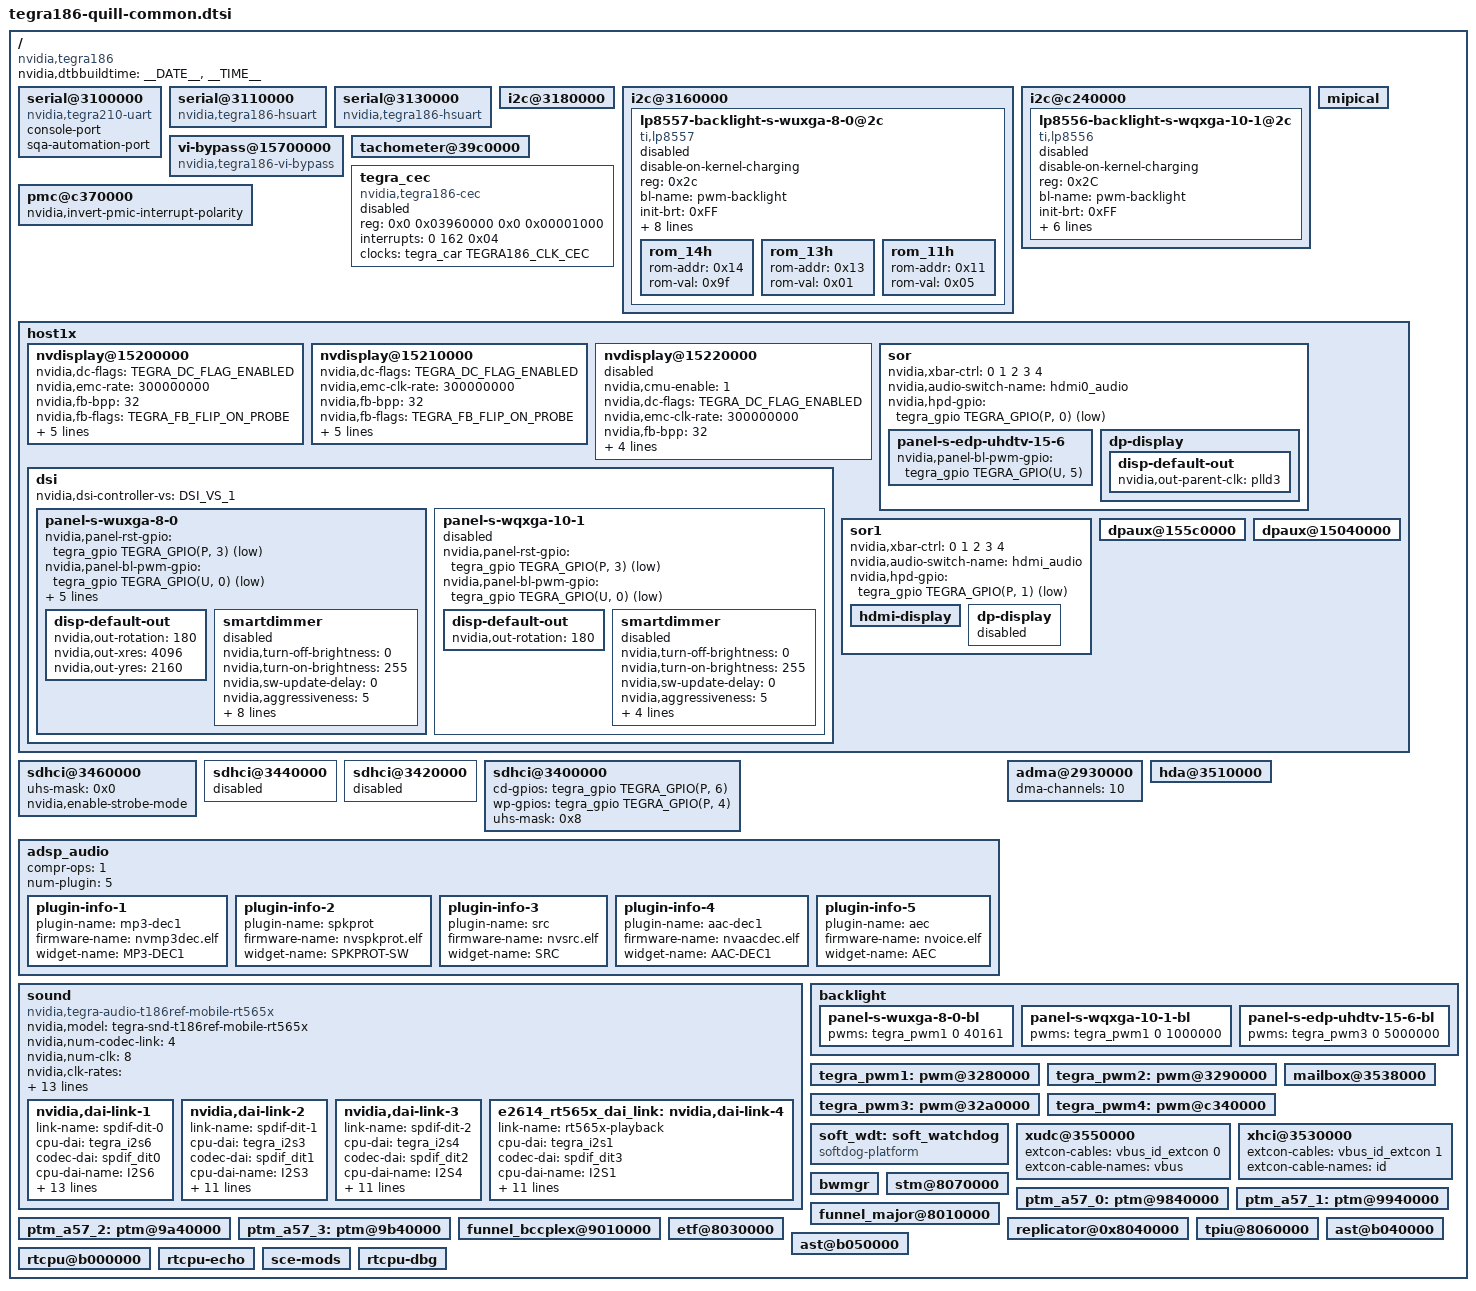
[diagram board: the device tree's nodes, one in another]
/*
 * tegra186-quill-common.dtsi: Quill common dtsi.
 *
 * Copyright (c) 2015-2016, NVIDIA CORPORATION.  All rights reserved.
 *
 * This program is free software; you can redistribute it and/or modify
 * it under the terms of the GNU General Public License as published by
 * the Free Software Foundation; version 2 of the License.
 *
 * This program is distributed in the hope that it will be useful, but WITHOUT
 * ANY WARRANTY; without even the implied warranty of MERCHANTABILITY or
 * FITNESS FOR A PARTICULAR PURPOSE.  See the GNU General Public License for
 * more details.
 */

#include <dt-bindings/types.h>
#include <dt-bindings/gpio/tegra-gpio.h>
/dts-v1/;

/memreserve/ 0x80000000 0x00010000;

#include "tegra186-soc/tegra186-soc-cvm.dtsi"
#include "tegra186-platforms-simple-bus.dtsi"
#include "panel-s-wuxga-8-0.dtsi"
#include "panel-s-wqxga-10-1.dtsi"
#include "tegra186-platforms/tegra186-quill-eqos.dtsi"
#include "tegra186-hdmi.dtsi"
#include "tegra186-dp.dtsi"
#include "panel-s-edp-uhdtv-15-6.dtsi"
#include "tegra186-quill-pwm-fan.dtsi"
#include "tegra186-quill-thermal-fan-est.dtsi"

/ {
        compatible = "nvidia,tegra186";

        nvidia,dtbbuildtime = __DATE__, __TIME__;
        #address-cells = <2>;
        #size-cells = <2>;

	serial@3100000 {
		compatible = "nvidia,tegra210-uart", "nvidia,tegra186-hsuart";
		console-port;
		sqa-automation-port;
		status = "okay";
	};

	serial@3110000 {
		compatible = "nvidia,tegra186-hsuart";
		status = "okay";
	};

	serial@3130000 {
		compatible = "nvidia,tegra186-hsuart";
		dma-names = "tx";
		status = "okay";
	};

	i2c@3180000 {
		status = "okay";
	};

	i2c@3160000 {
		status = "okay";
		lp8557-backlight-s-wuxga-8-0@2c {
			status = "disabled";
			disable-on-kernel-charging;
			compatible = "ti,lp8557";
			reg = <0x2c>;

			bl-name = "pwm-backlight"; /* Match liblights naming expectations */
			init-brt = /bits/ 8 <0xFF>; /* Max brightness */
			dev-ctrl = /bits/ 8 <0x80>; /* PWM, enable standby mode */
			pwm-period = <40161>;

			pwm-names = "lp8557";
			pwms = <&tegra_pwm1 0 40161>;

			bl-measured = < 0 1 2 3 4 5 5 6
					7 8 9 10 11 11 12 13
					14 15 15 16 17 18 19 20
					21 22 22 23 24 25 26 27
					28 29 30 31 31 32 33 34
					35 36 37 37 38 39 40 41
					41 42 43 44 45 46 47 48
					48 49 50 51 52 53 54 54
					55 56 57 58 58 59 60 61
					62 63 64 65 66 67 68 69
					70 71 72 73 74 75 75 76
					77 78 79 80 81 82 83 84
					85 86 87 88 89 90 91 92
					93 94 94 95 96 97 98 99
					100 101 102 104 105 106 107 108
					109 110 111 112 113 114 115 116
					117 118 119 120 121 122 123 125
					126 127 128 129 130 131 132 133
					134 135 136 137 138 139 140 141
					142 143 144 146 147 148 149 150
					151 152 153 154 155 156 157 158
					159 160 161 162 163 164 165 167
					168 169 170 171 172 173 174 175
					176 178 179 180 181 182 183 184
					185 186 187 188 189 190 191 192
					193 194 195 196 197 199 200 201
					202 203 204 205 206 207 208 210
					211 212 213 214 215 216 217 219
					220 221 222 223 225 226 227 228
					229 230 231 233 234 235 236 237
					238 239 240 241 242 244 245 246
					247 248 249 250 251 253 254 255 >;

			bl-curve = < 0 1 1 2 2 3 3 4
					4 5 5 6 7 7 8 8
					9 9 10 10 11 11 12 12
					13 14 14 15 15 16 16 17
					17 18 18 19 20 20 21 21
					22 22 23 23 24 24 25 25
					26 27 27 28 28 29 29 30
					30 31 31 32 33 33 34 34
					35 35 36 36 37 37 38 38
					39 40 40 41 41 42 42 43
					43 44 44 45 46 46 47 47
					48 48 49 49 50 50 51 52
					52 53 53 54 54 55 55 56
					56 57 57 58 59 59 60 60
					61 61 62 62 63 63 64 65
					65 66 66 67 67 68 68 69
					69 70 70 71 72 72 73 73
					74 74 75 75 76 76 77 78
					78 79 79 80 80 81 81 82
					82 83 83 84 85 85 86 86
					87 87 88 88 89 89 90 92
					94 96 97 99 101 103 105 107
					109 110 112 114 116 118 120 122
					123 125 127 129 131 133 134 136
					138 140 142 144 146 147 149 151
					153 155 157 159 160 162 164 166
					168 170 172 173 175 177 179 181
					183 185 186 188 190 192 194 196
					198 199 201 203 205 207 209 211
					212 214 216 218 220 222 223 225
					227 229 231 233 235 236 238 240
					242 244 246 248 249 251 253 255 >;

			/* 5 LED string */
			rom_14h {
				rom-addr = /bits/ 8 <0x14>;
				rom-val = /bits/ 8 <0x9f>;
			};

			/*Boost freq 1MHZ*/
			rom_13h {
				rom-addr = /bits/ 8 <0x13>;
				rom-val = /bits/ 8 <0x01>;
			};

			/*20mA max */
			rom_11h {
				rom-addr = /bits/ 8 <0x11>;
				rom-val = /bits/ 8 <0x05>;
			};
		};
	};

	i2c@c240000 {
		status = "okay";
		lp8556-backlight-s-wqxga-10-1@2c {
			status = "disabled";
			disable-on-kernel-charging;
			compatible = "ti,lp8556";
			reg = <0x2C>;

			bl-name = "pwm-backlight"; /* Match liblights naming expectations */
			init-brt = /bits/ 8 <0xFF>; /* Max brightness */
			dev-ctrl = /bits/ 8 <0x80>; /* PWM, enable standby mode */
			pwm-period = <40161>;

			pwm-names = "lp8556";
			pwms = <&tegra_pwm1 0 40161>;

			bl-measured = < 0 1 2 3 4 5 5 6
					7 8 9 10 11 11 12 13
					14 15 15 16 17 18 19 20
					21 22 22 23 24 25 26 27
					28 29 30 31 31 32 33 34
					35 36 37 37 38 39 40 41
					41 42 43 44 45 46 47 48
					48 49 50 51 52 53 54 54
					55 56 57 58 58 59 60 61
					62 63 64 65 66 67 68 69
					70 71 72 73 74 75 75 76
					77 78 79 80 81 82 83 84
					85 86 87 88 89 90 91 92
					93 94 94 95 96 97 98 99
					100 101 102 104 105 106 107 108
					109 110 111 112 113 114 115 116
					117 118 119 120 121 122 123 125
					126 127 128 129 130 131 132 133
					134 135 136 137 138 139 140 141
					142 143 144 146 147 148 149 150
					151 152 153 154 155 156 157 158
					159 160 161 162 163 164 165 167
					168 169 170 171 172 173 174 175
					176 178 179 180 181 182 183 184
					185 186 187 188 189 190 191 192
					193 194 195 196 197 199 200 201
					202 203 204 205 206 207 208 210
					211 212 213 214 215 216 217 219
					220 221 222 223 225 226 227 228
					229 230 231 233 234 235 236 237
					238 239 240 241 242 244 245 246
					247 248 249 250 251 253 254 255 >;
		};

	};

	vi-bypass@15700000{
		compatible = "nvidia,tegra186-vi-bypass";
		status = "okay";
	};

	tachometer@39c0000 {
		status = "okay";
	};

	tegra_cec {
		status = "disabled";
		compatible = "nvidia,tegra186-cec";
		reg = <0x0 0x03960000 0x0 0x00001000>;
		interrupts = <0 162 0x04>;
		clocks = <&tegra_car TEGRA186_CLK_CEC>;
		clock-names = "cec";
	};

	pmc@c370000 {
		nvidia,invert-pmic-interrupt-polarity;
	};

        mipical {
                status = "okay";
        };

	host1x {
		nvdisplay@15200000 {
                        status = "okay";
                        nvidia,dc-flags = <TEGRA_DC_FLAG_ENABLED>;
                        nvidia,emc-rate = <300000000>;
                        nvidia,fb-bpp = <32>;
                        nvidia,fb-flags = <TEGRA_FB_FLIP_ON_PROBE>;
			nvidia,fb-win = <0>;
			win-mask = <0x7>;
			nvidia,dc-ctrlnum = <0>;
			nvidia,dc-or-node = "/host1x/dsi";
			nvidia,cmu-enable = <1>;
                };

		nvdisplay@15210000 {
			status = "okay";
			nvidia,dc-flags = <TEGRA_DC_FLAG_ENABLED>;
			nvidia,emc-clk-rate = <300000000>;
			nvidia,fb-bpp = <32>; /* bits per pixel */
			nvidia,fb-flags = <TEGRA_FB_FLIP_ON_PROBE>;
			nvidia,fb-win = <3>;
			win-mask = <0x38>;
			nvidia,dc-ctrlnum = <1>;
			nvidia,dc-or-node = "/host1x/sor1";
			nvidia,cmu-enable = <1>;
		};

		nvdisplay@15220000 {
			nvidia,cmu-enable = <1>;
		};

		nvdisplay@15220000 {
			status = "disabled";
			nvidia,dc-flags = <TEGRA_DC_FLAG_ENABLED>;
			nvidia,emc-clk-rate = <300000000>;
			nvidia,fb-bpp = <32>; /* bits per pixel */
			nvidia,fb-flags = <TEGRA_FB_FLIP_ON_PROBE>;
			win-mask = <0x0>;
			nvidia,dc-ctrlnum = <2>;
			nvidia,dc-or-node = "/host1x/sor";
		};

		dsi {	/* dsi@15300000 */
			nvidia,dsi-controller-vs = <DSI_VS_1>;
			status = "okay";
			panel-s-wuxga-8-0 {
				status = "okay";
				nvidia,panel-rst-gpio = <&tegra_gpio TEGRA_GPIO(P, 3) 1>; /* PP3 */
				nvidia,panel-bl-pwm-gpio = <&tegra_gpio TEGRA_GPIO(U, 0) 1>; /* PU0 */
				nvidia,panel-bl-en-gpio = <&tegra_gpio TEGRA_GPIO(U, 3) 1>; /* PU3 */
				nvidia,panel-en-gpio = <&gpio_i2c_0_77 4 1>; /* tca9539 0x77 Pin 4 */
				nvidia,en-vmm-vpp-with-i2c-config;
				nvidia,default_color_space = <0>;
				disp-default-out {
					nvidia,out-rotation = <180>;
					nvidia,out-xres = <4096>;
					nvidia,out-yres = <2160>;
                                };
				smartdimmer {
					status = "disabled";
					nvidia,turn-off-brightness = <0>;
					nvidia,turn-on-brightness = <255>;
					nvidia,sw-update-delay = <0>;
					nvidia,aggressiveness = <5>;
					nvidia,phase-in-settings = <0>;
					nvidia,phase-in-adjustments = <0>;
					nvidia,sd-window-enable = <0>;
					nvidia,bl-device-name = "pwm-backlight";
					nvidia,gain_table = <
						0x4000 0x4000 0x4000 0x4000 0x4000 0x4000 0x4000 0x4000
						0x4000 0x4000 0x4000 0x4000 0x4000 0x4000 0x4000 0x4000
						0x4000 0x4000 0x4000 0x4000 0x4000 0x4000 0x4000 0x4000
						0x4000 0x4000 0x4000 0x4000 0x4000 0x4000 0x4000 0x4000
						0x4144 0x4144 0x4144 0x4144 0x4144 0x4144 0x4144 0x4144
						0x4144 0x4144 0x4144 0x4144 0x4144 0x4144 0x4144 0x4144
						0x4144 0x4144 0x4144 0x4144 0x4144 0x4144 0x4144 0x4144
						0x4144 0x4144 0x4144 0x4144 0x4144 0x4144 0x4144 0x4128
						0x428c 0x428c 0x428c 0x428c 0x428c 0x428c 0x428c 0x428c
						0x428c 0x428c 0x428c 0x428c 0x428c 0x428c 0x428c 0x428c
						0x428c 0x428c 0x428c 0x428c 0x428c 0x428c 0x428c 0x428c
						0x428c 0x428c 0x428c 0x428c 0x428c 0x428c 0x4260 0x4170
						0x43d4 0x43d4 0x43d4 0x43d4 0x43d4 0x43d4 0x43d4 0x43d4
						0x43d4 0x43d4 0x43d4 0x43d4 0x43d4 0x43d4 0x43d4 0x43d4
						0x43d4 0x43d4 0x43d4 0x43d4 0x43d4 0x43d4 0x43d4 0x43d4
						0x43d4 0x43d4 0x43d4 0x43d4 0x43d4 0x439c 0x42d0 0x4184
						0x451c 0x451c 0x451c 0x451c 0x451c 0x451c 0x451c 0x451c
						0x451c 0x451c 0x451c 0x451c 0x451c 0x451c 0x451c 0x451c
						0x451c 0x451c 0x451c 0x451c 0x451c 0x451c 0x451c 0x451c
						0x451c 0x451c 0x451c 0x451c 0x44ec 0x443c 0x4320 0x419c
						0x4664 0x4664 0x4664 0x4664 0x4664 0x4664 0x4664 0x4664
						0x4664 0x4664 0x4664 0x4664 0x4664 0x4664 0x4664 0x4664
						0x4664 0x4664 0x4664 0x4664 0x4664 0x4664 0x4664 0x4664
						0x4664 0x4664 0x4664 0x4620 0x457c 0x447c 0x432c 0x4198
						0x47ac 0x47ac 0x47ac 0x47ac 0x47ac 0x47ac 0x47ac 0x47ac
						0x47ac 0x47ac 0x47ac 0x47ac 0x47ac 0x47ac 0x47ac 0x47ac
						0x47ac 0x47ac 0x47ac 0x47ac 0x47ac 0x47ac 0x47ac 0x47ac
						0x47ac 0x47ac 0x476c 0x46d8 0x45f0 0x44bc 0x434c 0x41a0
						0x48f4 0x48f4 0x48f4 0x48f4 0x48f4 0x48f4 0x48f4 0x48f4
						0x48f4 0x48f4 0x48f4 0x48f4 0x48f4 0x48f4 0x48f4 0x48f4
						0x48f4 0x48f4 0x48f4 0x48f4 0x48f4 0x48f4 0x48f4 0x48f4
						0x48f4 0x48b8 0x482c 0x4758 0x463c 0x44e8 0x4360 0x41a4
						0x4a3c 0x4a3c 0x4a3c 0x4a3c 0x4a3c 0x4a3c 0x4a3c 0x4a3c
						0x4a3c 0x4a3c 0x4a3c 0x4a3c 0x4a3c 0x4a3c 0x4a3c 0x4a3c
						0x4a3c 0x4a3c 0x4a3c 0x4a3c 0x4a3c 0x4a3c 0x4a3c 0x4a3c
						0x4a04 0x4980 0x48b8 0x47b0 0x4674 0x4504 0x4368 0x41a8
						0x4b84 0x4b84 0x4b84 0x4b84 0x4b84 0x4b84 0x4b84 0x4b84
						0x4b84 0x4b84 0x4b84 0x4b84 0x4b84 0x4b84 0x4b84 0x4b84
						0x4b84 0x4b84 0x4b84 0x4b84 0x4b84 0x4b84 0x4b84 0x4b64
						0x4af4 0x4a3c 0x4948 0x481c 0x46c0 0x4538 0x4388 0x41b4
						0x4ccc 0x4ccc 0x4ccc 0x4ccc 0x4ccc 0x4ccc 0x4ccc 0x4ccc
						0x4ccc 0x4ccc 0x4ccc 0x4ccc 0x4ccc 0x4ccc 0x4ccc 0x4ccc
						0x4ccc 0x4ccc 0x4ccc 0x4ccc 0x4ccc 0x4ccc 0x4cac 0x4c40
						0x4b94 0x4aac 0x4990 0x4848 0x46d4 0x4540 0x4384 0x41b0
						0x4e14 0x4e14 0x4e14 0x4e14 0x4e14 0x4e14 0x4e14 0x4e14
						0x4e14 0x4e14 0x4e14 0x4e14 0x4e14 0x4e14 0x4e14 0x4e14
						0x4e14 0x4e14 0x4e14 0x4e14 0x4e14 0x4e04 0x4dac 0x4d10
						0x4c38 0x4b2c 0x49f0 0x4890 0x4708 0x455c 0x4398 0x41b8
						0x4f5c 0x4f5c 0x4f5c 0x4f5c 0x4f5c 0x4f5c 0x4f5c 0x4f5c
						0x4f5c 0x4f5c 0x4f5c 0x4f5c 0x4f5c 0x4f5c 0x4f5c 0x4f5c
						0x4f5c 0x4f5c 0x4f5c 0x4f5c 0x4f4c 0x4ef4 0x4e60 0x4d90
						0x4c90 0x4b64 0x4a10 0x489c 0x4708 0x4558 0x4390 0x41b0
						0x50a0 0x50a0 0x50a0 0x50a0 0x50a0 0x50a0 0x50a0 0x50a0
						0x50a0 0x50a0 0x50a0 0x50a0 0x50a0 0x50a0 0x50a0 0x50a0
						0x50a0 0x50a0 0x50a0 0x509c 0x5058 0x4fd4 0x4f10 0x4e20
						0x4d00 0x4bb8 0x4a50 0x48c8 0x4728 0x456c 0x439c 0x41b4
						0x51e8 0x51e8 0x51e8 0x51e8 0x51e8 0x51e8 0x51e8 0x51e8
						0x51e8 0x51e8 0x51e8 0x51e8 0x51e8 0x51e8 0x51e8 0x51e8
						0x51e8 0x51e8 0x51e8 0x51b8 0x5140 0x5090 0x4fa8 0x4e94
						0x4d5c 0x4c00 0x4a84 0x48ec 0x4740 0x4578 0x43a0 0x41b8
						0x5330 0x5330 0x5330 0x5330 0x5330 0x5330 0x5330 0x5330
						0x5330 0x5330 0x5330 0x5330 0x5330 0x5330 0x5330 0x5330
						0x5330 0x5330 0x5314 0x52ac 0x5208 0x5130 0x5028 0x4ef8
						0x4da8 0x4c38 0x4aac 0x4908 0x4750 0x4584 0x43a8 0x41b8
						0x5478 0x5478 0x5478 0x5478 0x5478 0x5478 0x5478 0x5478
						0x5478 0x5478 0x5478 0x5478 0x5478 0x5478 0x5478 0x5478
						0x5478 0x5468 0x5414 0x537c 0x52b0 0x51b4 0x5090 0x4f48
						0x4de4 0x4c64 0x4acc 0x491c 0x475c 0x4588 0x43a8 0x41b8
						0x55c0 0x55c0 0x55c0 0x55c0 0x55c0 0x55c0 0x55c0 0x55c0
						0x55c0 0x55c0 0x55c0 0x55c0 0x55c0 0x55c0 0x55c0 0x55c0
						0x55bc 0x5574 0x54ec 0x542c 0x533c 0x5224 0x50e8 0x4f8c
						0x4e14 0x4c84 0x4ae0 0x492c 0x4764 0x458c 0x43a8 0x41b8
						0x5708 0x5708 0x5708 0x5708 0x5708 0x5708 0x5708 0x5708
						0x5708 0x5708 0x5708 0x5708 0x5708 0x5708 0x5708 0x5708
						0x56d4 0x565c 0x55a8 0x54c0 0x53b0 0x5280 0x512c 0x4fbc
						0x4e38 0x4c9c 0x4af0 0x4934 0x4764 0x458c 0x43a8 0x41b8
						0x5850 0x5850 0x5850 0x5850 0x5850 0x5850 0x5850 0x5850
						0x5850 0x5850 0x5850 0x5850 0x5850 0x5850 0x5850 0x5830
						0x57c4 0x571c 0x5644 0x553c 0x5410 0x52c8 0x5160 0x4fe4
						0x4e50 0x4cac 0x4af8 0x4934 0x4764 0x458c 0x43a4 0x41b4
						0x5998 0x5998 0x5998 0x5998 0x5998 0x5998 0x5998 0x5998
						0x5998 0x5998 0x5998 0x5998 0x5998 0x5998 0x5990 0x5948
						0x58bc 0x57f4 0x56fc 0x55dc 0x549c 0x5340 0x51c8 0x503c
						0x4e9c 0x4ce8 0x4b28 0x495c 0x4784 0x45a0 0x43b0 0x41bc
						0x5ae0 0x5ae0 0x5ae0 0x5ae0 0x5ae0 0x5ae0 0x5ae0 0x5ae0
						0x5ae0 0x5ae0 0x5ae0 0x5ae0 0x5ae0 0x5ae0 0x5aa8 0x5a28
						0x596c 0x5880 0x5768 0x5630 0x54d8 0x5368 0x51e4 0x504c
						0x4ea0 0x4cec 0x4b24 0x4954 0x477c 0x4598 0x43ac 0x41b8
						0x5c28 0x5c28 0x5c28 0x5c28 0x5c28 0x5c28 0x5c28 0x5c28
						0x5c28 0x5c28 0x5c28 0x5c28 0x5c28 0x5c14 0x5bb4 0x5b10
						0x5a38 0x5930 0x5800 0x56b4 0x554c 0x53cc 0x5238 0x5090
						0x4edc 0x4d1c 0x4b4c 0x4974 0x4790 0x45a8 0x43b4 0x41bc
						0x5d70 0x5d70 0x5d70 0x5d70 0x5d70 0x5d70 0x5d70 0x5d70
						0x5d70 0x5d70 0x5d70 0x5d70 0x5d68 0x5d18 0x5c84 0x5bb0
						0x5ab0 0x598c 0x5844 0x56e0 0x5568 0x53dc 0x523c 0x5090
						0x4ed4 0x4d10 0x4b40 0x4964 0x4784 0x459c 0x43ac 0x41b8
						0x5eb8 0x5eb8 0x5eb8 0x5eb8 0x5eb8 0x5eb8 0x5eb8 0x5eb8
						0x5eb8 0x5eb8 0x5eb8 0x5eb8 0x5e90 0x5e18 0x5d60 0x5c70
						0x5b54 0x5a18 0x58bc 0x574c 0x55c0 0x5428 0x527c 0x50c4
						0x4f00 0x4d34 0x4b5c 0x497c 0x4794 0x45a8 0x43b4 0x41bc
						0x6000 0x6000 0x6000 0x6000 0x6000 0x6000 0x6000 0x6000
						0x6000 0x6000 0x6000 0x5ff8 0x5fa4 0x5f04 0x5e28 0x5d1c
						0x5be8 0x5a98 0x592c 0x57a8 0x5610 0x5468 0x52b4 0x50f4
						0x4f28 0x4d54 0x4b74 0x4990 0x47a4 0x45b0 0x43bc 0x41c0
						0x6144 0x6144 0x6144 0x6144 0x6144 0x6144 0x6144 0x6144
						0x6144 0x6144 0x6144 0x6104 0x6074 0x5fa0 0x5e9c 0x5d70
						0x5c24 0x5abc 0x593c 0x57ac 0x5608 0x545c 0x52a0 0x50dc
						0x4f0c 0x4d38 0x4b5c 0x4978 0x4790 0x45a0 0x43b0 0x41b8
						0x628c 0x628c 0x628c 0x628c 0x628c 0x628c 0x628c 0x628c
						0x628c 0x628c 0x6278 0x6208 0x614c 0x605c 0x5f3c 0x5df8
						0x5c94 0x5b1c 0x5990 0x57f0 0x5644 0x548c 0x52c8 0x50fc
						0x4f28 0x4d4c 0x4b6c 0x4984 0x4798 0x45a8 0x43b4 0x41bc
						0x63d4 0x63d4 0x63d4 0x63d4 0x63d4 0x63d4 0x63d4 0x63d4
						0x63d4 0x63d4 0x6390 0x62f4 0x6214 0x6100 0x5fc8 0x5e70
						0x5cfc 0x5b74 0x59d8 0x5830 0x5678 0x54b8 0x52ec 0x5118
						0x4f40 0x4d60 0x4b78 0x4990 0x47a0 0x45ac 0x43b4 0x41bc
						0x651c 0x651c 0x651c 0x651c 0x651c 0x651c 0x651c 0x651c
						0x651c 0x6504 0x648c 0x63c4 0x62c4 0x6198 0x6044 0x5ed8
						0x5d54 0x5bbc 0x5a14 0x5860 0x56a4 0x54d8 0x5308 0x5130
						0x4f50 0x4d6c 0x4b84 0x4994 0x47a4 0x45b0 0x43b8 0x41bc
						0x6664 0x6664 0x6664 0x6664 0x6664 0x6664 0x6664 0x6664
						0x6664 0x6618 0x6570 0x6480 0x6360 0x6218 0x60b4 0x5f34
						0x5da0 0x5bfc 0x5a4c 0x588c 0x56c4 0x54f4 0x5320 0x5140
						0x4f60 0x4d78 0x4b8c 0x499c 0x47a8 0x45b0 0x43b8 0x41bc
						0x67ac 0x67ac 0x67ac 0x67ac 0x67ac 0x67ac 0x67ac 0x67ac
						0x6790 0x670c 0x6638 0x6528 0x63ec 0x628c 0x6110 0x5f80
						0x5de0 0x5c30 0x5a74 0x58b0 0x56e0 0x550c 0x5330 0x5150
						0x4f68 0x4d7c 0x4b90 0x499c 0x47a8 0x45b0 0x43b8 0x41bc
						0x68f4 0x68f4 0x68f4 0x68f4 0x68f4 0x68f4 0x68f4 0x68f4
						0x68a0 0x67e8 0x66e8 0x65b8 0x6460 0x62ec 0x6160 0x5fc4
						0x5e14 0x5c5c 0x5a98 0x58c8 0x56f4 0x551c 0x533c 0x5158
						0x4f6c 0x4d80 0x4b90 0x499c 0x47a8 0x45b0 0x43b8 0x41bc
						0x6a3c 0x6a3c 0x6a3c 0x6a3c 0x6a3c 0x6a3c 0x6a3c 0x6a1c
						0x698c 0x68a4 0x6784 0x6634 0x64c4 0x633c 0x61a4 0x5ff8
						0x5e40 0x5c7c 0x5ab0 0x58dc 0x5704 0x5524 0x5340 0x5158
						0x4f70 0x4d80 0x4b90 0x499c 0x47a8 0x45b0 0x43b4 0x41bc
						0x6b84 0x6b84 0x6b84 0x6b84 0x6b84 0x6b84 0x6b80 0x6b24
						0x6a5c 0x6948 0x6804 0x669c 0x6518 0x6380 0x61d4 0x6020
						0x5e5c 0x5c94 0x5ac0 0x58e8 0x570c 0x5528 0x5344 0x5158
						0x4f6c 0x4d7c 0x4b8c 0x4998 0x47a4 0x45ac 0x43b4 0x41b8
						0x6ccc 0x6ccc 0x6ccc 0x6ccc 0x6ccc 0x6ccc 0x6cc0 0x6c3c
						0x6b54 0x6a2c 0x68d4 0x6758 0x65c8 0x6420 0x6268 0x60a8
						0x5ed8 0x5d04 0x5b28 0x5948 0x5760 0x5578 0x5388 0x5198
						0x4fa4 0x4dac 0x4bb4 0x49b8 0x47bc 0x45c0 0x43c0 0x41c0
						0x6e14 0x6e14 0x6e14 0x6e14 0x6e14 0x6e14 0x6dd0 0x6d0c
						0x6bf4 0x6aa4 0x6930 0x67a0 0x65fc 0x6448 0x6288 0x60bc
						0x5ee8 0x5d0c 0x5b2c 0x5948 0x575c 0x5570 0x5380 0x5190
						0x4f9c 0x4da4 0x4bac 0x49b0 0x47b8 0x45b8 0x43bc 0x41bc
						0x6f5c 0x6f5c 0x6f5c 0x6f5c 0x6f5c 0x6f4c 0x6eb8 0x6db8
						0x6c74 0x6b08 0x697c 0x67d8 0x6624 0x6464 0x6298 0x60c4
						0x5ee8 0x5d08 0x5b24 0x593c 0x5754 0x5564 0x5374 0x5184
						0x4f8c 0x4d98 0x4ba0 0x49a8 0x47b0 0x45b4 0x43b8 0x41bc
						0x70a0 0x70a0 0x70a0 0x70a0 0x70a0 0x7054 0x6f74 0x6e40
						0x6cdc 0x6b50 0x69b0 0x67fc 0x663c 0x6470 0x629c 0x60c4
						0x5ee4 0x5d00 0x5b18 0x5930 0x5744 0x5554 0x5364 0x5174
						0x4f80 0x4d88 0x4b94 0x499c 0x47a4 0x45ac 0x43b4 0x41b8
						0x71e8 0x71e8 0x71e8 0x71e8 0x71e8 0x7168 0x7064 0x6f14
						0x6d98 0x6bfc 0x6a4c 0x688c 0x66c0 0x64e8 0x630c 0x612c
						0x5f44 0x5d58 0x5b6c 0x5978 0x5788 0x5590 0x539c 0x51a4
						0x4fa8 0x4db0 0x4bb4 0x49b8 0x47b8 0x45bc 0x43bc 0x41bc
						0x7330 0x7330 0x7330 0x7330 0x7300 0x7220 0x70e4 0x6f6c
						0x6dd0 0x6c20 0x6a60 0x6894 0x66bc 0x64e0 0x62fc 0x6118
						0x5f2c 0x5d40 0x5b50 0x5960 0x576c 0x5578 0x5384 0x518c
						0x4f94 0x4d9c 0x4ba4 0x49a8 0x47ac 0x45b4 0x43b8 0x41bc
						0x7478 0x7478 0x7478 0x7478 0x7414 0x730c 0x71b0 0x7020
						0x6e74 0x6cb4 0x6ae8 0x6910 0x6730 0x654c 0x6360 0x6174
						0x5f80 0x5d8c 0x5b98 0x59a0 0x57a8 0x55b0 0x53b4 0x51b8
						0x4fb8 0x4dbc 0x4bbc 0x49c0 0x47c0 0x45c0 0x43c0 0x41c0
						0x75c0 0x75c0 0x75c0 0x75a8 0x74d0 0x7380 0x71f4 0x7048
						0x6e84 0x6cb4 0x6adc 0x68fc 0x6714 0x652c 0x633c 0x614c
						0x5f5c 0x5d68 0x5b74 0x597c 0x5784 0x558c 0x5394 0x5198
						0x4fa0 0x4da4 0x4ba8 0x49ac 0x47b0 0x45b4 0x43b8 0x41bc
						0x7708 0x7708 0x7708 0x76c4 0x75b4 0x7440 0x729c 0x70e0
						0x6f10 0x6d34 0x6b50 0x6968 0x6778 0x6588 0x6394 0x619c
						0x5fa4 0x5dac 0x5bb0 0x59b4 0x57b8 0x55bc 0x53bc 0x51c0
						0x4fc0 0x4dc0 0x4bc0 0x49c0 0x47c0 0x45c0 0x43c0 0x41c0
						0x7850 0x7850 0x784c 0x7778 0x7610 0x746c 0x72a8 0x70d4
						0x6ef4 0x6d10 0x6b24 0x6938 0x6744 0x6554 0x635c 0x6168
						0x5f70 0x5d78 0x5b80 0x5988 0x578c 0x5590 0x5398 0x519c
						0x4fa0 0x4da4 0x4ba8 0x49ac 0x47b0 0x45b4 0x43b8 0x41bc
						0x7998 0x7998 0x7974 0x7854 0x76c4 0x7504 0x7330 0x7150
						0x6f68 0x6d78 0x6b84 0x6990 0x6798 0x65a0 0x63a4 0x61a8
						0x5fac 0x5db0 0x5bb4 0x59b8 0x57b8 0x55b8 0x53bc 0x51bc
						0x4fbc 0x4dbc 0x4bc0 0x49c0 0x47c0 0x45c0 0x43c0 0x41c0
						0x7ae0 0x7ae0 0x7a1c 0x788c 0x76c4 0x74e8 0x7304 0x7114
						0x6f24 0x6d34 0x6b3c 0x6948 0x6750 0x6558 0x6360 0x6164
						0x5f6c 0x5d74 0x5b78 0x5980 0x5784 0x5588 0x5390 0x5194
						0x4f98 0x4d9c 0x4ba4 0x49a8 0x47ac 0x45b0 0x43b4 0x41bc
						0x7c28 0x7c20 0x7ae4 0x7928 0x7748 0x755c 0x736c 0x7174
						0x6f7c 0x6d84 0x6b88 0x6990 0x6794 0x6598 0x6398 0x619c
						0x5fa0 0x5da0 0x5ba4 0x59a8 0x57a8 0x55ac 0x53ac 0x51b0
						0x4fb0 0x4db4 0x4bb4 0x49b8 0x47b8 0x45b8 0x43bc 0x41bc
						0x7d70 0x7d28 0x7b88 0x79a8 0x77b8 0x75c0 0x73c8 0x71cc
						0x6fcc 0x6dcc 0x6bd0 0x69d0 0x67d0 0x65d0 0x63d0 0x61d0
						0x5fcc 0x5dcc 0x5bcc 0x59cc 0x57cc 0x55c8 0x53c8 0x51c8
						0x4fc8 0x4dc4 0x4bc4 0x49c4 0x47c4 0x45c0 0x43c0 0x41c0
						0x7eb8 0x7d30 0x7b38 0x7940 0x7744 0x7548 0x734c 0x7154
						0x6f58 0x6d5c 0x6b60 0x6964 0x6768 0x656c 0x6370 0x6174
						0x5f78 0x5d7c 0x5b84 0x5988 0x578c 0x5590 0x5394 0x5198
						0x4f9c 0x4da0 0x4ba4 0x49a8 0x47ac 0x45b0 0x43b4 0x41bc
						0x8000 0x7dfc 0x7bf8 0x79f8 0x77f4 0x75f4 0x73f0 0x71f0
						0x6fec 0x6dec 0x6be8 0x69e8 0x67e4 0x65e4 0x63e0 0x61e0
						0x5fdc 0x5ddc 0x5bd8 0x59d8 0x57d4 0x55d4 0x53d0 0x51d0
						0x4fcc 0x4dcc 0x4bc8 0x49c8 0x47c4 0x45c4 0x43c0 0x41c0
					>;
					nvidia,backlight_table = <
						255 245 235 226 217 209 201 194 187 180 174 168 162 157
						152 147 142 138 134 130 126 122 119 115 112 109 106 103
						100 98 95 93 90 88 86 84 82 80 78 76 74 73 71 69 68 66
						65 63 62 61 59
					>;
				};
			};
			panel-s-wqxga-10-1 {
				status = "disabled";
				nvidia,panel-rst-gpio = <&tegra_gpio TEGRA_GPIO(P, 3) 1>; /* PP3 */
				nvidia,panel-bl-pwm-gpio = <&tegra_gpio TEGRA_GPIO(U, 0) 1>; /* PU0 */
				disp-default-out {
					nvidia,out-rotation = <180>;
				};
				smartdimmer {
					status = "disabled";
					nvidia,turn-off-brightness = <0>;
					nvidia,turn-on-brightness = <255>;
					nvidia,sw-update-delay = <0>;
					nvidia,aggressiveness = <5>;
					nvidia,phase-in-settings = <0>;
					nvidia,phase-in-adjustments = <0>;
					nvidia,sd-window-enable = <0>;
					nvidia,bl-device-name = "pwm-backlight";
				};
			};
		};

		sor{
			status = "okay";
			nvidia,xbar-ctrl = <0 1 2 3 4>;
			nvidia,audio-switch-name = "hdmi0_audio";
			nvidia,hpd-gpio = <&tegra_gpio TEGRA_GPIO(P, 0) GPIO_ACTIVE_LOW>;
			panel-s-edp-uhdtv-15-6 {
				nvidia,panel-bl-pwm-gpio = <&tegra_gpio TEGRA_GPIO(U, 5) 0>;
			};

			dp-display {
				disp-default-out {
					nvidia,out-parent-clk = "plld3";
				};
			};
		};
		sor1 {
			status = "okay";
			nvidia,xbar-ctrl = <0 1 2 3 4>;
			nvidia,audio-switch-name = "hdmi_audio";
			nvidia,hpd-gpio = <&tegra_gpio TEGRA_GPIO(P, 1) GPIO_ACTIVE_LOW>;
			hdmi-display {
				status = "okay";
			};

			dp-display {
				status = "disabled";
			};
		};
		dpaux@155c0000 {
			status = "okay";
		};
		dpaux@15040000 {
			status = "okay";
		};
	};

	sdhci@3460000 {
		uhs-mask = <0x0>; /*enable HS400 mode*/
		nvidia,enable-strobe-mode;
		status = "okay";
	};

	sdhci@3440000 {
		status = "disabled";
	};

	sdhci@3420000 {
		status = "disabled";
	};

	sdhci@3400000 {
		cd-gpios = <&tegra_gpio TEGRA_GPIO(P, 6) 0>;
		wp-gpios = <&tegra_gpio TEGRA_GPIO(P, 4) 0>;
		uhs-mask = <0x8>;
		status = "okay";
	};

	adsp_audio {
		compr-ops = <1>;
		num-plugin = <5>;
		plugin-info-1 {
			plugin-name = "mp3-dec1";
			firmware-name = "nvmp3dec.elf";
			widget-name = "MP3-DEC1";
		};
		plugin-info-2 {
			plugin-name = "spkprot";
			firmware-name = "nvspkprot.elf";
			widget-name = "SPKPROT-SW";
		};
		plugin-info-3 {
			plugin-name = "src";
			firmware-name = "nvsrc.elf";
			widget-name = "SRC";
		};
		plugin-info-4 {
			plugin-name = "aac-dec1";
			firmware-name = "nvaacdec.elf";
			widget-name = "AAC-DEC1";
		};
		plugin-info-5 {
			plugin-name = "aec";
			firmware-name = "nvoice.elf";
			widget-name = "AEC";
		};
	};

	adma@2930000 {
		dma-channels = <10>;
	};

	hda@3510000 {
		status = "okay";
       };

	sound {
		compatible = "nvidia,tegra-audio-t186ref-mobile-rt565x";
		nvidia,model = "tegra-snd-t186ref-mobile-rt565x";
		nvidia,num-codec-link = <4>;
		nvidia,num-clk = <8>;
		nvidia,clk-rates = < 270950400	/* PLLA_x11025_RATE */
				     11289600	/* AUD_MCLK_x11025_RATE */
				     45158400	/* PLLA_OUT0_x11025_RATE */
				     45158400	/* AHUB_x11025_RATE */
				     344063944  /* PLLA_x8000_RATE */
				     12288000	/* AUD_MCLK_x8000_RATE */
				     49152000	/* PLLA_OUT0_x8000_RATE */
				     49152000 >;/* AHUB_x8000_RATE */
		clocks = <&tegra_car TEGRA186_CLK_PLLP_OUT0>,
			<&tegra_car TEGRA186_CLK_PLLA>,
			<&tegra_car TEGRA186_CLK_PLL_A_OUT0>,
			<&tegra_car TEGRA186_CLK_AHUB>,
			<&tegra_car TEGRA186_CLK_CLK_M>,
			<&tegra_car TEGRA186_CLK_AUD_MCLK>;
		clock-names = "pll_p_out1", "pll_a", "pll_a_out0", "ahub",
				"clk_m", "extern1";
		resets = <&tegra_car TEGRA186_RESET_AUD_MCLK>;
		reset-names = "extern1_rst";

		status = "okay";
		nvidia,audio-routing =
			"y Headphone",		"y OUT",
			"y IN",			"y Mic",
			"z IN",			"z OUT",
			"m Headphone",		"m OUT",
			"m IN",			"m Mic",
			"x Headphone",		"x OUT",
			"x IN",			"x Mic";

		nvidia,xbar = <&tegra_axbar>;

		nvidia,dai-link-1 {
			link-name = "spdif-dit-0";
			cpu-dai = <&tegra_i2s6>;
			codec-dai = <&spdif_dit0>;
			cpu-dai-name = "I2S6";
			codec-dai-name = "dit-hifi";
			tx-mask = <0xFF>;
			rx-mask = <0xFF>;
			format = "dsp_a";
			bitclock-slave;
			frame-slave;
			bitclock-inversion;
			frame-inversion;
			bit-format = "s16_le";
			bclk_ratio = <4>;
			srate = <8000>;
			num-channel = <1>;
			name-prefix = "y";
		};
		nvidia,dai-link-2 {
			link-name = "spdif-dit-1";
			cpu-dai = <&tegra_i2s3>;
			codec-dai = <&spdif_dit1>;
			cpu-dai-name = "I2S3";
			codec-dai-name = "dit-hifi";
			format = "i2s";
			bitclock-slave;
			frame-slave;
			bitclock-noninversion;
			frame-noninversion;
			bit-format = "s16_le";
			bclk_ratio = <1>;
			srate = <48000>;
			num-channel = <2>;
			name-prefix = "z";
		};
		nvidia,dai-link-3 {
			link-name = "spdif-dit-2";
			cpu-dai = <&tegra_i2s4>;
			codec-dai = <&spdif_dit2>;
			cpu-dai-name = "I2S4";
			codec-dai-name = "dit-hifi";
			format = "i2s";
			bitclock-slave;
			frame-slave;
			bitclock-noninversion;
			frame-noninversion;
			bit-format = "s16_le";
			bclk_ratio = <1>;
			srate = <48000>;
			num-channel = <2>;
			name-prefix = "m";
		};
		e2614_rt565x_dai_link: nvidia,dai-link-4 {
			link-name = "rt565x-playback";
			cpu-dai = <&tegra_i2s1>;
			codec-dai = <&spdif_dit3>;
			cpu-dai-name = "I2S1";
			codec-dai-name = "dit-hifi";
			format = "i2s";
			bitclock-slave;
			frame-slave;
			bitclock-noninversion;
			frame-noninversion;
			bit-format = "s16_le";
			bclk_ratio = <0>;
			srate = <48000>;
			num-channel = <2>;
			name-prefix = "x";
		};
	};

	backlight {
		status = "okay";
		panel-s-wuxga-8-0-bl {
			pwms = <&tegra_pwm1 0 40161>;
		};
		panel-s-wqxga-10-1-bl {
			pwms = <&tegra_pwm1 0 1000000>;
		};
                panel-s-edp-uhdtv-15-6-bl {
                        pwms = <&tegra_pwm3 0 5000000>;
                };
	};

	tegra_pwm1: pwm@3280000 {
		status = "okay";
	};

	tegra_pwm2: pwm@3290000 {
		status = "okay";
	};

	tegra_pwm3: pwm@32a0000 {
		status = "okay";
	};

	tegra_pwm4: pwm@c340000 {
		status = "okay";
	};

	soft_wdt:soft_watchdog {
		compatible = "softdog-platform";
		status = "okay";
	};

	mailbox@3538000 {
		status = "okay";
	};

	xudc@3550000 {
		extcon-cables = <&vbus_id_extcon 0>;
		extcon-cable-names = "vbus";
		#extcon-cells = <1>;
	};

	xhci@3530000 {
		extcon-cables = <&vbus_id_extcon 1>;
		extcon-cable-names = "id";
		#extcon-cells = <1>;
	};

	bwmgr {
		status = "okay";
	};

	stm@8070000 {
		status = "okay";
	};

	ptm_a57_0: ptm@9840000 {
		status = "okay";
	};

	ptm_a57_1: ptm@9940000 {
		status = "okay";
	};

	ptm_a57_2: ptm@9a40000 {
		status = "okay";
	};

	ptm_a57_3: ptm@9b40000 {
		status = "okay";
	};

	funnel_bccplex@9010000 {
		status = "okay";
	};

	funnel_major@8010000 {
		status = "okay";
	};

	replicator@0x8040000 {
		status = "okay";
	};

	etf@8030000 {
		status = "okay";
	};

	tpiu@8060000 {
		status = "okay";
	};

	ast@b040000 {
		status = "okay";
	};

	ast@b050000 {
		status = "okay";
	};

	rtcpu@b000000 {
		status = "okay";
	};

	rtcpu-echo {
		status = "okay";
	};

	sce-mods {
		status = "okay";
	};

	rtcpu-dbg {
		status = "okay";
	};
};
